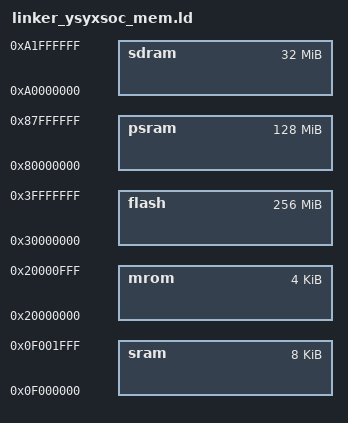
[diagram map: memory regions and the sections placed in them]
MEMORY {
  sram : ORIGIN = 0x0f000000, LENGTH = 0x2000
  mrom : ORIGIN = 0x20000000, LENGTH = 0x1000
  flash : ORIGIN = 0x30000000, LENGTH = 0x10000000
  psram : ORIGIN = 0x80000000, LENGTH = 0x8000000
  sdram : ORIGIN = 0xa0000000, LENGTH = 0x2000000
}
